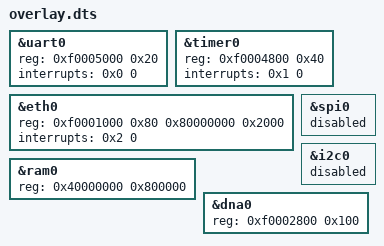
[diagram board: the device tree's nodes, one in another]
&uart0 {
    reg = <0xf0005000 0x20>;
    interrupts = <0x0 0>;
};
&timer0 {
    reg = <0xf0004800 0x40>;
    interrupts = <0x1 0>;
};
&eth0 {
    reg = <0xf0001000 0x80 0x80000000 0x2000>;
    interrupts = <0x2 0>;
};
&spi0 {
    status = "disabled";
};
&i2c0 {
    status = "disabled";
};
&ram0 {
    reg = <0x40000000 0x800000>;
};
&dna0 {
    reg = <0xf0002800 0x100>;
};
